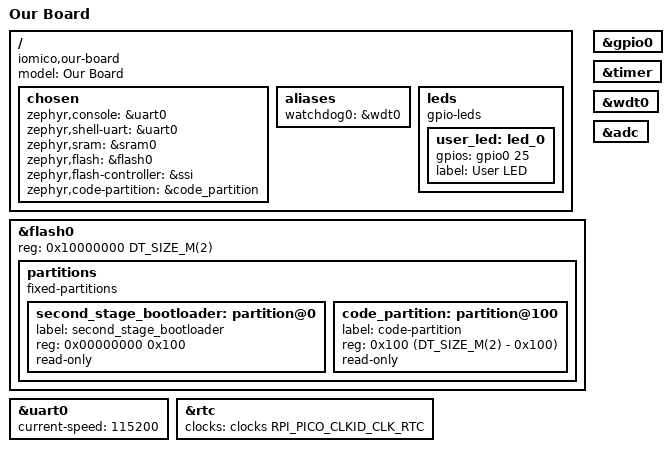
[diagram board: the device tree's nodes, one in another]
/dts-v1/;

#include <raspberrypi/rpi_pico/rp2040.dtsi>
#include <zephyr/dt-bindings/gpio/gpio.h>

/ {
    model = "Our Board";
    compatible = "iomico,our-board";

    chosen {
        zephyr,console = &uart0;
        zephyr,shell-uart = &uart0;
        zephyr,sram = &sram0;
        zephyr,flash = &flash0;
        zephyr,flash-controller = &ssi;
        zephyr,code-partition = &code_partition;
    };

    aliases {
        watchdog0 = &wdt0;
    };

    leds {
        compatible = "gpio-leds";
        user_led: led_0 {
            gpios = <&gpio0 25 GPIO_ACTIVE_HIGH>;
            label = "User LED";
        };
    };
};

&flash0 {
    reg = <0x10000000 DT_SIZE_M(2)>;

    partitions {
        compatible = "fixed-partitions";
        #address-cells = <1>;
        #size-cells = <1>;

        second_stage_bootloader: partition@0 {
            label = "second_stage_bootloader";
            reg = <0x00000000 0x100>;
            read-only;
        };

        code_partition: partition@100 {
            label = "code-partition";
            reg = <0x100 (DT_SIZE_M(2) - 0x100)>;
            read-only;
        };
    };
};

&uart0 {
    current-speed = <115200>;
    status = "okay";
};

&gpio0 {
    status = "okay";
};

&timer {
    status = "okay";
};

&wdt0 {
    status = "okay";
};

&rtc {
    clocks = <&clocks RPI_PICO_CLKID_CLK_RTC>;
    status = "okay";
};

&adc {
    status = "okay";
};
